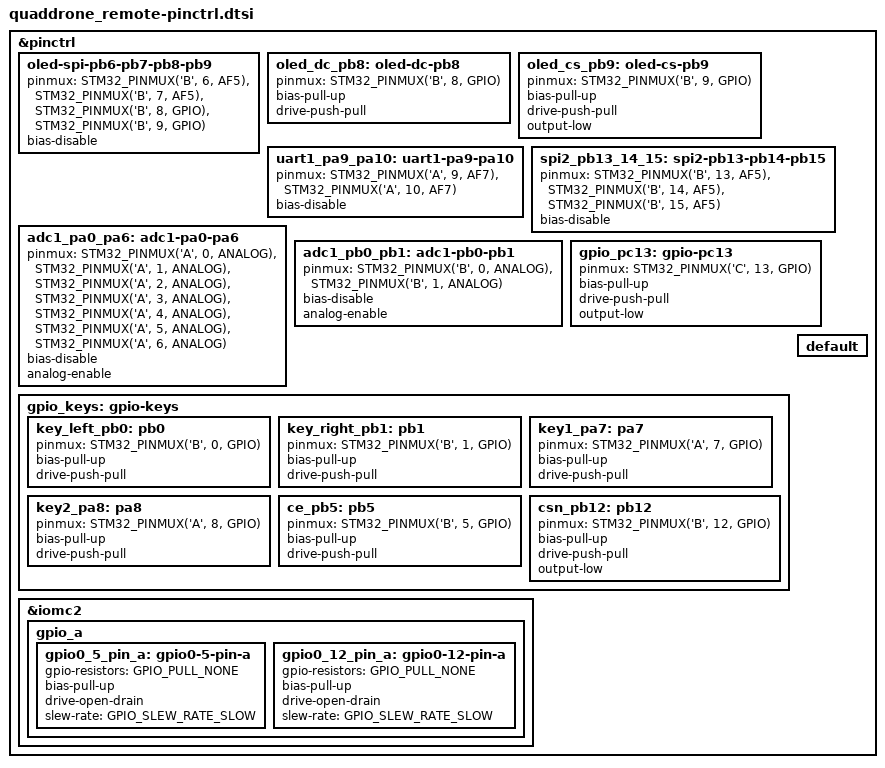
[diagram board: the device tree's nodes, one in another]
/*
 * Copyright (c) 2024 QuadDrone Project. SPDX-License-Identifier: Apache-2.0
 */

&pinctrl {
  oled-spi-gpios: oled-spi-pb6-pb7-pb8-pb9 {
    pinmux = <STM32_PINMUX('B', 6, AF5)>,
             <STM32_PINMUX('B', 7, AF5)>,
             <STM32_PINMUX('B', 8, GPIO)>,
             <STM32_PINMUX('B', 9, GPIO)>;
    bias-disable;
  };

  oled_dc_pb8: oled-dc-pb8 {
    pinmux = <STM32_PINMUX('B', 8, GPIO)>;
    bias-pull-up;
    drive-push-pull;
  };

  oled_cs_pb9: oled-cs-pb9 {
    pinmux = <STM32_PINMUX('B', 9, GPIO)>;
    bias-pull-up;
    drive-push-pull;
    output-low;
  };

  uart1_pa9_pa10: uart1-pa9-pa10 {
    pinmux = <STM32_PINMUX('A', 9, AF7)>,
             <STM32_PINMUX('A', 10, AF7)>;
    bias-disable;
  };

  spi2_pb13_14_15: spi2-pb13-pb14-pb15 {
    pinmux = <STM32_PINMUX('B', 13, AF5)>,
             <STM32_PINMUX('B', 14, AF5)>,
             <STM32_PINMUX('B', 15, AF5)>;
    bias-disable;
  };

  adc1_pa0_pa6: adc1-pa0-pa6 {
    pinmux = <STM32_PINMUX('A', 0, ANALOG)>,
             <STM32_PINMUX('A', 1, ANALOG)>,
             <STM32_PINMUX('A', 2, ANALOG)>,
             <STM32_PINMUX('A', 3, ANALOG)>,
             <STM32_PINMUX('A', 4, ANALOG)>,
             <STM32_PINMUX('A', 5, ANALOG)>,
             <STM32_PINMUX('A', 6, ANALOG)>;
    bias-disable;
    analog-enable;
  };

  adc1_pb0_pb1: adc1-pb0-pb1 {
    pinmux = <STM32_PINMUX('B', 0, ANALOG)>,
             <STM32_PINMUX('B', 1, ANALOG)>;
    bias-disable;
    analog-enable;
  };

  gpio_pc13: gpio-pc13 {
    pinmux = <STM32_PINMUX('C', 13, GPIO)>;
    bias-pull-up;
    drive-push-pull;
    output-low;
  };

  gpio_keys: gpio-keys {
    key_left_pb0: pb0 {
      pinmux = <STM32_PINMUX('B', 0, GPIO)>;
      bias-pull-up;
      drive-push-pull;
    };
    key_right_pb1: pb1 {
      pinmux = <STM32_PINMUX('B', 1, GPIO)>;
      bias-pull-up;
      drive-push-pull;
    };
    key1_pa7: pa7 {
      pinmux = <STM32_PINMUX('A', 7, GPIO)>;
      bias-pull-up;
      drive-push-pull;
    };
    key2_pa8: pa8 {
      pinmux = <STM32_PINMUX('A', 8, GPIO)>;
      bias-pull-up;
      drive-push-pull;
    };
    ce_pb5: pb5 {
      pinmux = <STM32_PINMUX('B', 5, GPIO)>;
      bias-pull-up;
      drive-push-pull;
    };
    csn_pb12: pb12 {
      pinmux = <STM32_PINMUX('B', 12, GPIO)>;
      bias-pull-up;
      drive-push-pull;
      output-low;
    };
  };

  &iomc2 {
	gpio_a {
		gpio0_5_pin_a: gpio0-5-pin-a {
			gpio-resistors = <GPIO_PULL_NONE>;
			bias-pull-up;
			drive-open-drain;
			slew-rate = GPIO_SLEW_RATE_SLOW;
		};
		gpio0_12_pin_a: gpio0-12-pin-a {
			gpio-resistors = <GPIO_PULL_NONE>;
			bias-pull-up;
			drive-open-drain;
			slew-rate = GPIO_SLEW_RATE_SLOW;
		};
	};
  };

  default {
    /* Default pin states can be defined here if needed */
  };
};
